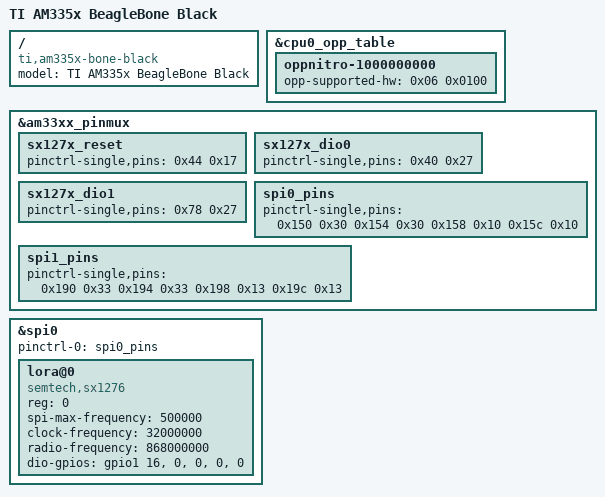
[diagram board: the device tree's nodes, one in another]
/dts-v1/;

#include "am33xx.dtsi"
#include "am335x-bone-common.dtsi"
#include "am335x-boneblack-common.dtsi"

/ {
	model = "TI AM335x BeagleBone Black";
	compatible = "ti,am335x-bone-black", "ti,am335x-bone", "ti,am33xx";
};

&cpu0_opp_table {
	/*
	 * All PG 2.0 silicon may not support 1GHz but some of the early
	 * BeagleBone Blacks have PG 2.0 silicon which is guaranteed
	 * to support 1GHz OPP so enable it for PG 2.0 on this board.
	 */
	oppnitro-1000000000 {
		opp-supported-hw = <0x06 0x0100>;
	};
};

&am33xx_pinmux {
	sx127x_reset: sx127x_reset {
		/* OUTPUT_PULLUP MODE7 */
		pinctrl-single,pins = <0x44 0x17>;
	};

	sx127x_dio0: sx127x_dio0 {
		/* INPUT_PULLDOWN */
		pinctrl-single,pins = <0x40 0x27>;
	};

	sx127x_dio1: sx127x_dio1 {
		/* INPUT_PULLDOWN */
		pinctrl-single,pins = <0x78 0x27>;
	};

	spi0_pins: spi0_pins {
		pinctrl-single,pins = <
			0x150 0x30  /* spi0_sclk, INPUT_PULLUP | MODE0 */
			0x154 0x30  /* spi0_d0, INPUT_PULLUP | MODE0 */
			0x158 0x10  /* spi0_d1, OUTPUT_PULLUP | MODE0 */
			0x15c 0x10  /* spi0_cs0, OUTPUT_PULLUP | MODE0 */
		>;
	};

	spi1_pins: spi1_pins {
		pinctrl-single,pins = <
			0x190 0x33      /* mcasp0_aclkx.spi1_sclk, INPUT_PULLUP | MODE3 */
			0x194 0x33      /* mcasp0_fsx.spi1_d0, INPUT_PULLUP | MODE3 */
			0x198 0x13      /* mcasp0_axr0.spi1_d1, OUTPUT_PULLUP | MODE3 */
			0x19c 0x13      /* mcasp0_ahclkr.spi1_cs0, OUTPUT_PULLUP | MODE3 */
		>;
	};
};

&spi0 {
	status="okay";
	pinctrl-names = "default";
	pinctrl-0 = <&spi0_pins>;
	lora@0 {
		status="okay";
		compatible = "semtech,sx1276";
		reg = <0>;
		spi-max-frequency = <500000>;
		clock-frequency = <32000000>;
		radio-frequency = <868000000>;
		/*
		* RESET == 1_17 == 49
		* DIO0  == 1_16 == 48
		* DIO1  == 1_28 == 60
		* DIO2
		* DIO3
		* DIO4
		* DIO5
		*/
		/*reset-gpios = <&gpio1 17 0>;*/
		dio-gpios = <&gpio1 16 0>,
		            <0>,
		            <0>,
		            <0>,
		            <0>;
	};
};
